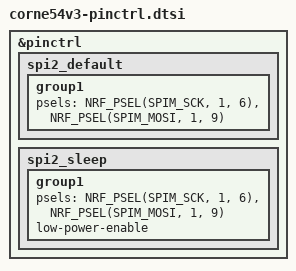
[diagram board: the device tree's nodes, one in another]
/*
 * Copyright (c) 2023 The ZMK Contributors
 * SPDX-License-Identifier: MIT
 */

&pinctrl {
    spi2_default: spi2_default {
        group1 {
            psels = <NRF_PSEL(SPIM_SCK, 1, 6)>,
                    <NRF_PSEL(SPIM_MOSI, 1, 9)>; // WS2812_VEXT_DATA
        };
    };

    spi2_sleep: spi2_sleep {
        group1 {
            psels = <NRF_PSEL(SPIM_SCK, 1, 6)>,
                    <NRF_PSEL(SPIM_MOSI, 1, 9)>;
            low-power-enable;
        };
    };
};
